# haltium_sysctrl register map
Vendor: Nordic Semiconductor; Series: nRFHaltium; File version: 1
Registers are 32-bit, read-write, reset 0x0 unless marked. A register's access mark holds for its fields unless they carry their own. Offsets are from the block's base; [hi:lo] are bit positions; lines under a group give offsets from that group; 'fields as' and 'values as' point back to an identical list.

## VREGAO0V8_S — VREGAO0V8
Base 0x5F964000
0x400 STATUS ro — Voltage regulator status
  [1:0] MODE — Current voltage regulator mode
    0=High power mode; 1=Low power refresh mode; 2=Ultra-low power refresh mode; 3=Bypass forced mode
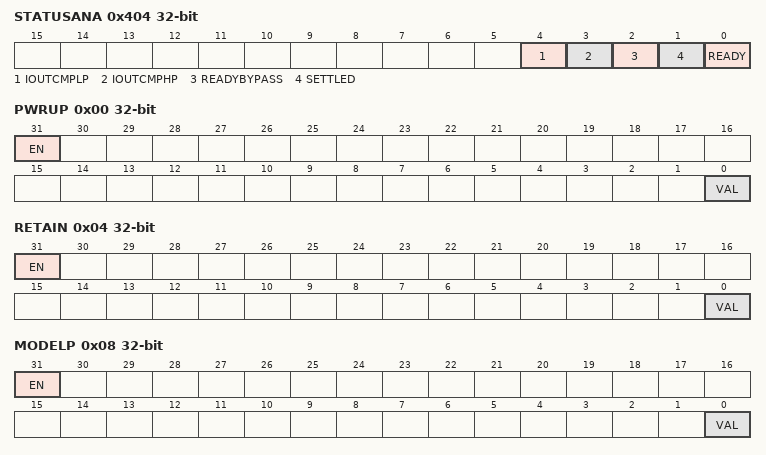
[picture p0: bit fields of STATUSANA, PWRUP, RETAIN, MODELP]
0x404 STATUSANA ro — Status of analog module output signals
  [4] IOUTCMPLP — Current value of the IOUTCMPLP signal from the analog module
  [3] IOUTCMPHP — Current value of the IOUTCMPHP signal from the analog module
  [2] READYBYPASS — Current value of the READYBYPASS signal from the analog module
  [1] SETTLED — Current value of the SETTLED signal from the analog module
  [0] READY — Current value of the READY signal from the analog module
0x410 CONFIG group — Unspecified
  0x00 CFGSTATIC — VREGAO0V8 static CFG configuration
  0x04 CFGDYNAMIC — VREGAO0V8 dynamic CFG configuration
    [1:0] DOUBLEBIAS — Double bias current configuration for the voltage regulator
      0=Automatically handled by the MMI; 1=Disabled (Configuration disabled); 2=Enabled (Configuration enabled)
0x440 TRIM group — Unspecified
  0x00 VREF — Internal voltage reference trimming
    [6:0] VAL — Voltage reference trimming value
  0x04 HIGHPOWER — High power mode output voltage offset trimming
    [3:0] VAL — Voltage offset trimming value
  0x08 LOWPOWER — Low power mode output voltage offset trimming
    [3:0] VAL — Voltage offset trimming value.
0x480 MIRROR reset 0x1 — Enable LOCK for mirrored registers
  [0] LOCK — Lock for mirrored registers
    0=Disabled (Lock disabled); 1=Enabled (Lock enabled)
0x484 VOUT reset 0x3 — Output voltage programming
  [2:0] VAL — Output voltage value
0x488 PWRUPCTRL — Power up control
  [1:0] CTRL
    0=Automatically handled by the MMI; 1=PowerUp; 2=PowerDown
0x48C MODE — Voltage regulator mode
  [2:0] MODE
    0=Automatically handled by the MMI; 1=High power mode; 2=Low power refresh mode; 3=Ultra-low power refresh mode; 4=Bypass forced mode
0x500 OVERRIDE group — Unspecified
  0x00 PWRUP — Override the PWRUP signal to the analog module
    [31] EN — Enable the override
      0=Disabled (Override is disabled); 1=Enabled (Override is enabled)
    [0] VAL — Override value for the signal
  0x04 RETAIN — Override the RETAIN signal to the analog module
    fields as OVERRIDE.PWRUP
  0x08 MODELP — Override the MODE LP signal to the analog module
    fields as OVERRIDE.PWRUP
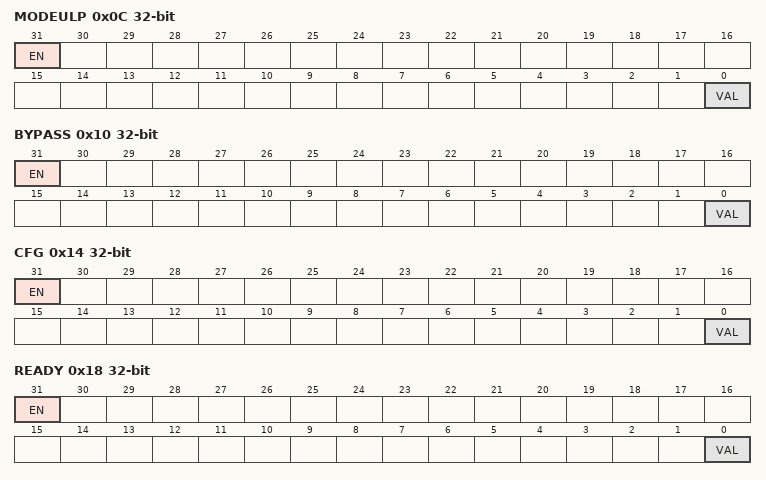
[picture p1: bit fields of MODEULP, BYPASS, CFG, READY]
  0x0C MODEULP — Override the MODE ULP signal to the analog module
    fields as OVERRIDE.PWRUP
  0x10 BYPASS — Override the BYPASS signal to the analog module
    fields as OVERRIDE.PWRUP
  0x14 CFG — Override the dynamic CFG[0] signal to the analog module
    fields as OVERRIDE.PWRUP
  0x18 READY — Override the READY signal from the analog module
    [31] EN — Enable the override
      values as OVERRIDE.PWRUP.EN
    [0] VAL — Current value of the signal
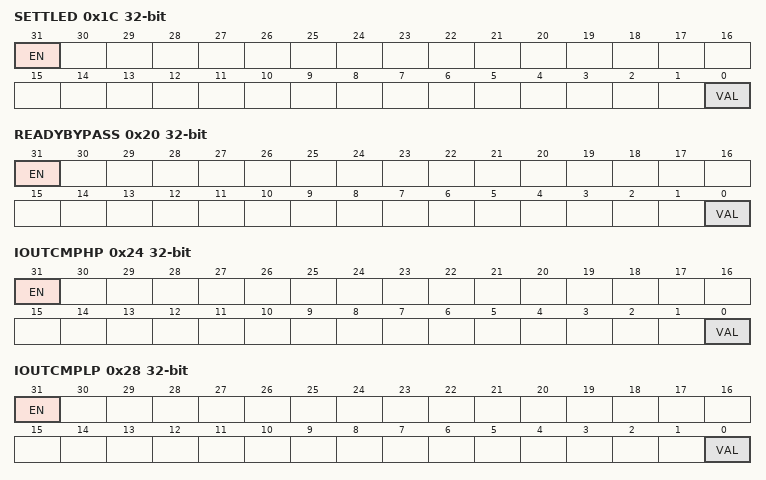
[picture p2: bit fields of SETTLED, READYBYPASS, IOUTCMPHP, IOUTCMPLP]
  0x1C SETTLED — Override the SETTLED signal from the analog module
    fields as OVERRIDE.READY
  0x20 READYBYPASS — Read the READY_BYPASS signal from the analog module
    fields as OVERRIDE.READY
  0x24 IOUTCMPHP — Read the IOUTCMP_HP signal from the analog module
    fields as OVERRIDE.READY
  0x28 IOUTCMPLP — Read the IOUTCMP_LP signal from the analog module
    fields as OVERRIDE.READY
0x600 DFT group — Unspecified
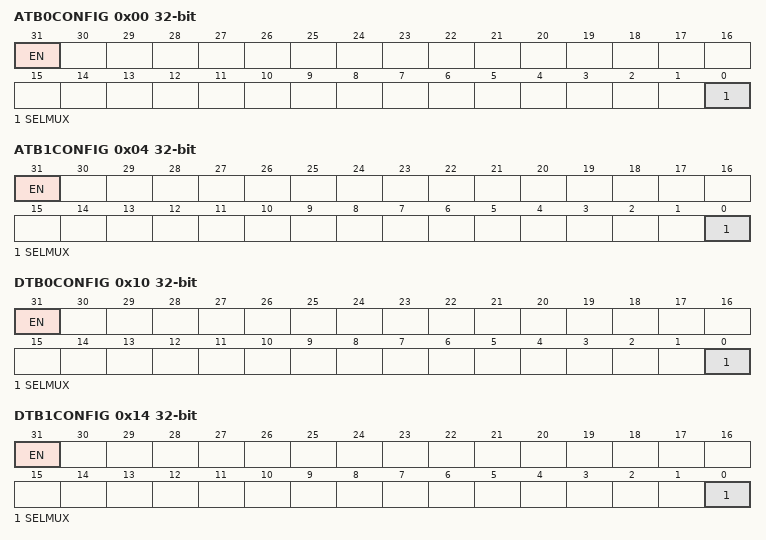
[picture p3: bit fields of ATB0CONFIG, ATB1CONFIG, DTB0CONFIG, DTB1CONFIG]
  0x00 ATB0CONFIG — Analog Test Bus 0 (ATB0) configuration
    [31] EN — Enable the analog test bus
      0=Disabled (Analog test bus is disabled); 1=Enabled (Analog test bus is enabled)
    [0] SELMUX — Select multiplexer for ATB0
      0=ExtVref (External Vref); 1=VSS
  0x04 ATB1CONFIG — Analog Test Bus 1 (ATB1) configuration
    [31] EN — Enable the analog test bus
      values as DFT.ATB0CONFIG.EN
    [0] SELMUX — Select multiplexer for ATB1
      0=UnbufferedHPvref; 1=VDDAO0V8
  0x10 DTB0CONFIG — Digital Test Bus 0 (DTB0) configuration
    [31] EN — Enable the digital test bus
      0=Disabled (Digital test bus is disabled); 1=Enabled (Digital test bus is enabled)
    [0] SELMUX — Select multiplexer for DTB0
      0=None selected; 1=Settled
  0x14 DTB1CONFIG — Digital Test Bus 1 (DTB1) configuration
    [31] EN — Enable the digital test bus
      values as DFT.DTB0CONFIG.EN
    [0] SELMUX — Select multiplexer for DTB1
      0=None selected; 1=Ready
  0x1C DTB3CONFIG — Digital Test Bus 3 (DTB3) configuration
    [30] PWRUPDELTEST — Enable the PWRUP delay test circuit
      0=Disabled (PWRUP delay test circuit is disabled); 1=Enabled (PWRUP delay test circuit is enabled)
  0x30 TCFG — Test mode configuration
    [5:0] MODE
      0=Off; 5=PowerupHPcore; 6=PowerupBias
  0x34 CALEN — Calibration enable
    [0] CALEN
      0=ATCMPOff; 1=ATCMPOn
  0x38 CALCMP ro — Calibration compare
    [0] CALCMP
